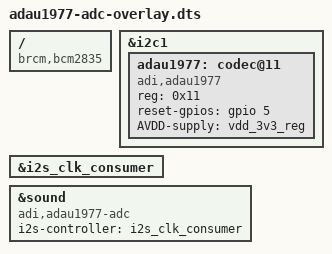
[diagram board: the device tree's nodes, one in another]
// Definitions for ADAU1977 ADC
/dts-v1/;
/plugin/;

/ {
	compatible = "brcm,bcm2835";
    
	fragment@0 {
		target = <&i2c1>;
        	
		__overlay__ {
			#address-cells = <1>;
			#size-cells = <0>;
			status = "okay";
			
			adau1977: codec@11 {
                        	compatible = "adi,adau1977";
                        	reg = <0x11>;
                        	reset-gpios = <&gpio 5 0>;
				AVDD-supply = <&vdd_3v3_reg>;
                	};
        	};
	};

	fragment@1 {
		target = <&i2s_clk_consumer>;
		__overlay__ {
			status = "okay";
		};
	};

	fragment@2 {
		target = <&sound>;
		__overlay__ {
			compatible = "adi,adau1977-adc";
			i2s-controller = <&i2s_clk_consumer>;
			status = "okay";
		};
	};
};
